# MKW38A4 register map
Vendor: NXP Semiconductors; Series: Kinetis_W; File version: 1.6
CPU: CM0PLUS r0p0, little endian, no MPU, no FPU, VTOR, 2 interrupt priority bits
Registers are 32-bit, read-write, no defined reset value unless marked. A register's access mark holds for its fields unless they carry their own. Offsets are from the block's base; [hi:lo] are bit positions.

## RBME
Base 0x40086200
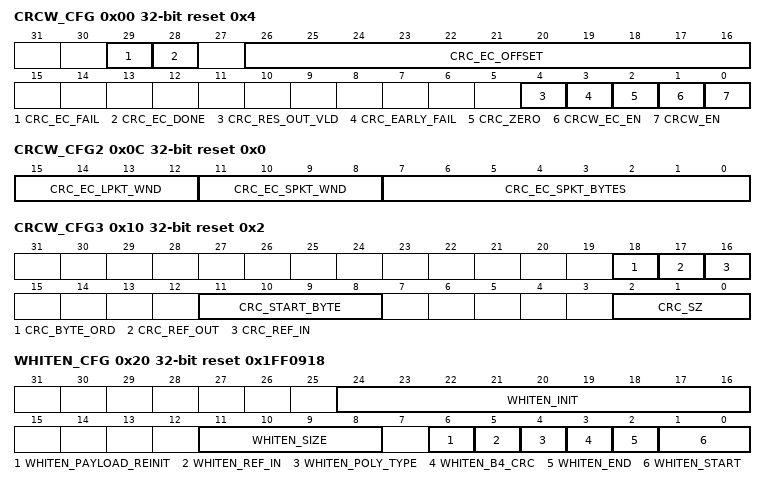
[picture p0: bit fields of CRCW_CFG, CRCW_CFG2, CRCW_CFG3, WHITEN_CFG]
0x00 CRCW_CFG reset 0x4 — CRC/WHITENER CONFIG REGISTER
  [29] CRC_EC_FAIL ro — CRC error correction fail
  [28] CRC_EC_DONE ro — CRC error correction done
  [26:16] CRC_EC_OFFSET ro — CRC error correction offset
  [4] CRC_RES_OUT_VLD ro — CRC result output valid
  [3] CRC_EARLY_FAIL ro — CRC error correction fail
  [2] CRC_ZERO ro
  [1] CRCW_EC_EN — CRC Error Correction Enable
  [0] CRCW_EN — CRC calculation enable
0x04 CRC_EC_MASK ro reset 0x0 — CRC ERROR CORRECTION MASK
  [31:0] CRC_EC_MASK — CRC error correction mask
0x08 CRC_RES_OUT ro reset 0x0 — CRC RESULT
  [31:0] CRC_RES_OUT — CRC result output
0x0C CRCW_CFG2 reset 0x0 — CRC/WHITENER CONFIG 2 REGISTER
  [15:12] CRC_EC_LPKT_WND — Error correction long packet burst error window
  [11:8] CRC_EC_SPKT_WND — Error correction short packet burst error window
  [7:0] CRC_EC_SPKT_BYTES — Error Correction Short Packet Bytes
0x10 CRCW_CFG3 reset 0x2 — CRC CONFIGURATION
  [18] CRC_BYTE_ORD — CRC Byte Order
    0=LS Byte First; 1=MS Byte First
  [17] CRC_REF_OUT — CRC Reflect Out
    0=Does not manipulate CRC result; 1=CRC result is to be reflected bitwise (operated on entire word)
  [16] CRC_REF_IN — CRC Reflect In
    0=Does not manipulate input data stream; 1=reflect each byte in the input stream bitwise
  [11:8] CRC_START_BYTE — Configure CRC Start Point
  [2:0] CRC_SZ — CRC Size (in octets)
0x14 CRC_INIT reset 0x0 — CRC INITIALIZATION
  [31:0] CRC_SEED — CRC Seed Value
0x18 CRC_POLY reset 0x10210000 — CRC POLYNOMIAL
  [31:0] CRC_POLY — CRC Polynomial.
0x1C CRC_XOR_OUT reset 0x0
0x20 WHITEN_CFG reset 0x1FF0918 — WHITENER CONFIGURATION
  [24:16] WHITEN_INIT — Initialization value for whitening/de-whitening
  [11:8] WHITEN_SIZE — Length of Whitener LFSR
  [6] WHITEN_PAYLOAD_REINIT — Configure for Whitener re-initialization
    0=Does not re-initialize Whitener LFSR at start-of-payload; 1=Re-initialize Whitener LFSR at start-of-payload
  [5] WHITEN_REF_IN — Whiten Reflect Input
  [4] WHITEN_POLY_TYPE — Whiten Polynomial Type
  [3] WHITEN_B4_CRC — Congifure for Whitening-before-CRC
    0=CRC before whiten/de-whiten; 1=Whiten/de-whiten before CRC
  [2] WHITEN_END — Configure end-of-whitening
    0=end whiten at end-of-payload; 1=end whiten at end-of-crc
  [1:0] WHITEN_START — Configure Whitener Start Point
    0=no whitening; 1=start whitening at start-of-H0; 2=start whitening at start-of-H1 but only if LENGTH > WHITEN_SZ_THR; 3=start whitening at start-of-payload but only if LENGTH > WHITEN_SZ_THR
0x24 WHITEN_POLY reset 0x21 — WHITENER POLYNOMIAL
  [8:0] WHITEN_POLY — Whitener Polynomial
0x28 WHITEN_SZ_THR reset 0x800 — WHITENER SIZE THRESHOLD
  [11:0] WHITEN_SZ_THR — Whitener Size Threshold
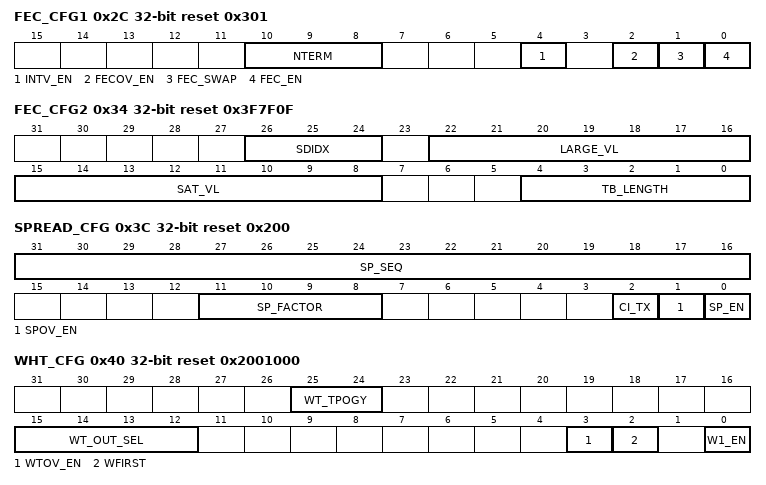
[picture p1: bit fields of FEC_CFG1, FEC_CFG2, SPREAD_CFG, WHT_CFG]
0x2C FEC_CFG1 reset 0x301 — FEC CONFIG REGISTER 1
  [10:8] NTERM — Number of term bits
  [4] INTV_EN — Enable interleaver reigster
    1=Enable interleaver for 15.4 and LEG0; 0=Disable interleaver for 802.15.4 and LEG0
  [2] FECOV_EN — Enable dynamic overide of FEC
    1=The override of FEC is only used in 802.15.4, dynamically depending on the SFD pattern received; 0=Disable FEC override
  [1] FEC_SWAP — Choose 802.15.4 swap mode of FEC operation
    0=Disable Swap operation for FEC; 1=Swap for 802.15.4 and LEG0
  [0] FEC_EN — FEC enable
    0=Disable FEC encoder and decoder; 1=Enable FEC encoder and decoder
0x30 RBME_RST reset 0x0 — RBME SOFT RESET REGISTER
  [0] RBME_RST — RBME reset signal
    0=Disable soft reset; 1=Enable soft reset. When this bit is write to 1, the soft reset to RBME happens immediately. Then all internal registers and functions will be reset.
0x34 FEC_CFG2 reset 0x3F7F0F — FEC CONFIG REGISTER 2
  [26:24] SDIDX — Index of startup state. PM(startStIdx)=0
  [22:16] LARGE_VL — Large value used at startup phase, assigned to the initial PMs.
  [15:8] SAT_VL — Saturation value for PM
  [4:0] TB_LENGTH — Trace-back length
0x38 FLUSH_CFG reset 0x0 — FEC FLUSH CONFIG REGISTER
  [0] FLUSH_CFG — FLUSH CLOCK CONFIG BIT
    0=32M flush clock; 1=26M flush clock
0x3C SPREAD_CFG reset 0x200 — SPREADER CONFIG REGISTER
  [31:16] SP_SEQ — Spreading Bit Sequence
  [11:8] SP_FACTOR — Spreading Factor
  [2] CI_TX — Bluetooth LE
    0=FEC Block 2 coded using S=8; 1=FEC Block 2 coded using S=2
  [1] SPOV_EN — Spreader Override Enable
    0=Does not allow active override of the spreading enable; 1=Allows active override of the spreading enable
  [0] SP_EN — Spreader Enable bit
    0=Disable spreader; 1=Enable spreader
0x40 WHT_CFG reset 0x2001000 — WHITEN CONFIG REGISTER
  [25:24] WT_TPOGY — Whiten 1 Polynomial Type
  [15:12] WT_OUT_SEL — Selected Output
  [3] WTOV_EN — Allows overwrite of the whitening
  [2] WFIRST — Whitens before CRC
  [0] W1_EN — Enable first whitener
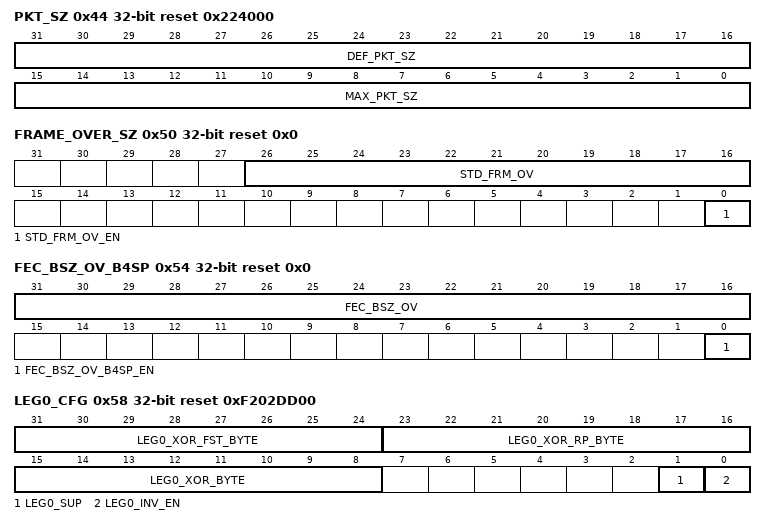
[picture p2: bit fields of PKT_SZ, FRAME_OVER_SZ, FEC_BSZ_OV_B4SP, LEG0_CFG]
0x44 PKT_SZ reset 0x224000 — PACKET SIZE REGISTER
  [31:16] DEF_PKT_SZ — Default Packet Size
  [15:0] MAX_PKT_SZ — Maximum Packet Size In Bits
0x48 CRC_PHR_SZ reset 0x3 — LENGTH OF PHR CONFIG REGISTER
  [2:0] PHR_SZ — PHR Size Config
0x4C FCP_CFG reset 0x0 — FCP SUPPORT CONFIG REGISTER
  [0] FCP_SUPPORT — FCP Suppport
    0=Disable FCP support; 1=Enable FCP support
0x50 FRAME_OVER_SZ reset 0x0 — FRAME OVERRIDE SIZE REGISTER
  [26:16] STD_FRM_OV — Value to overide the STD frame length (bits)
  [0] STD_FRM_OV_EN — Overrides actvie STD frame length from link layer enable bit
    0=Disable override actvie STD frame length from link layer; 1=Enable override actvie STD frame length from link layer
0x54 FEC_BSZ_OV_B4SP reset 0x0 — OVERRIDE OF FEC BLOCK SIZE REGISTER
  [31:16] FEC_BSZ_OV — Value of the override in bits. It is for test purpose.
  [0] FEC_BSZ_OV_B4SP_EN — Override of the FEC block size for data
    0=Disable Override actvie STD frame length from link layer; 1=Enable Override actvie STD frame length from link layer
0x58 LEG0_CFG reset 0xF202DD00 — LEG0 CONFIG REGISTER
  [31:24] LEG0_XOR_FST_BYTE — FEC first byte masking
  [23:16] LEG0_XOR_RP_BYTE — LEG0 repeat bytes masking
  [15:8] LEG0_XOR_BYTE — LEG0 whitening masking byte
  [1] LEG0_SUP — LEG0 support register
    0=Disable LEG0 support; 1=Enable LEG0 support
  [0] LEG0_INV_EN — Whiten invert enable bit
    0=Disable whiten invert for LEG0; 1=Enable whiten invert for LEG0
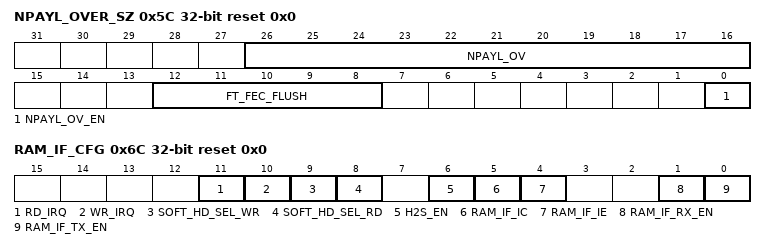
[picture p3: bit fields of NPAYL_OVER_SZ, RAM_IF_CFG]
0x5C NPAYL_OVER_SZ reset 0x0 — OVERRIDE PAYLOAD LENGTH REGISTER
  [26:16] NPAYL_OV
  [12:8] FT_FEC_FLUSH — Value to overide the payload length (bits)
  [0] NPAYL_OV_EN — Override the internal payload length computation
    0=Disable override the internal payload length; 1=Enable override the internal payload length
0x60 DATALL_CFG reset 0x0 — DATA TO LINK LAYER CONFIG REGISTER
  [0] DELAY_EN — Data to link layer delay enable bit
    0=Disable delay in 32M; 1=Enable delay in 26M
0x64 RAM_S_ADDR reset 0x0 — PACKET RAM SOURCE ADDRESS
  [13:0] RAM_S_ADDR — Packet RAM source address. This address is ram physical address.
0x68 RAM_D_ADDR reset 0x0 — PACKET RAM DESTINATION ADDRESS
  [13:0] RAM_D_ADDR — Packet RAM destination address, this address is ram physical address.
0x6C RAM_IF_CFG reset 0x0 — PACKET RAM INTERFACE CONFIG REGISTER
  [11] RD_IRQ ro — Read to RAM complete flag
    0=Reading to RAM not complete; 1=Reading to RAM complete
  [10] WR_IRQ ro — Write to RAM complete flag
    0=Writing to RAM not complete; 1=Writing to RAM complete
  [9] SOFT_HD_SEL_WR — Soft and hard bit selection of read operation
    0=Hard bit selection of read operation; 1=Soft bit selection of read operation
  [8] SOFT_HD_SEL_RD — Soft and hard bit selection of write operation
    0=Hard bit selection of write operation; 1=Soft bit selection of write operation
  [6] H2S_EN — Hard bit convert to soft bit enable
    0=Disable hard bit to soft bits coversion; 1=Enable hard bit to soft bits coversion
  [5] RAM_IF_IC — RAM interface interrupt clear
    0=To do nothing to RAM interface interrupt; 1=To clear RAM interface interrupt
  [4] RAM_IF_IE — RAM interface interrupt enable bit
    0=Disable RAM interface interrupt; 1=Enable RAM interface interrupt
  [1] RAM_IF_RX_EN — RAM interface RX enable
    0=Disable RAM interface RX; 1=Enable RAM interface RX
  [0] RAM_IF_TX_EN — RAM interface TX enable bit
    0=Disable RAM interface TX; 1=Enable RAM interface TX
